AUTOSAR XML (schema 4.0)
package /Powertrain
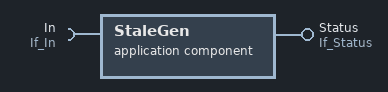
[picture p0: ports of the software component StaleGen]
  application sw component type StaleGen
    require port In: required-interface=If_In
    provide port Status: provided-interface=If_Status
